# ATSAM4LC2C register map
Vendor: Atmel Corporation; Series: SAM4L; File version: B
CPU: CM4 r0p1, little endian, MPU, no FPU, 4 interrupt priority bits
Registers are 32-bit, write-only, reset 0x0 unless marked. A register's access mark holds for its fields unless they carry their own. Offsets are from the block's base; [hi:lo] are bit positions; 'fields as' and 'values as' point back to an identical list.

## TWIM0 — Two-wire Master Interface 0
Base 0x40018000; register names take the prefix TWIM_
Same registers: TWIM1 0x4001C000, TWIM2 0x40078000, TWIM3 0x4007C000
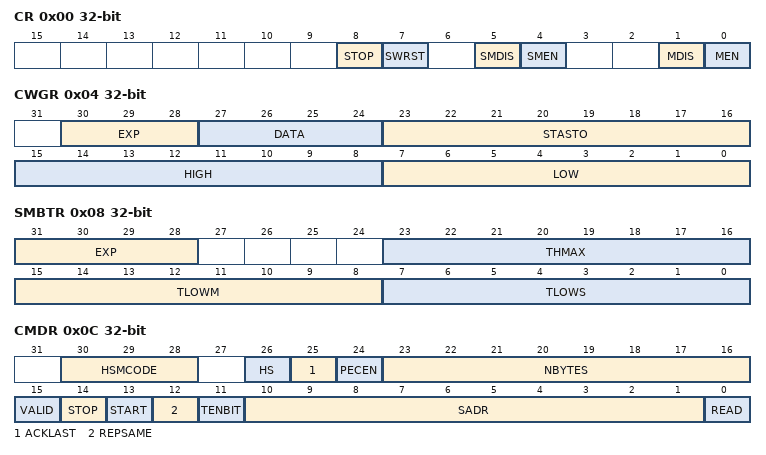
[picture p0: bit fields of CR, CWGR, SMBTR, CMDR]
0x00 CR — Control Register
  [8] STOP — Stop the current transfer
  [7] SWRST — Software Reset
  [5] SMDIS — SMBus Disable
  [4] SMEN — SMBus Enable
  [1] MDIS — Master Disable
  [0] MEN — Master Enable
0x04 CWGR rw — Clock Waveform Generator Register
  [30:28] EXP — Clock Prescaler
  [27:24] DATA — Data Setup and Hold Cycles
  [23:16] STASTO — START and STOP Cycles
  [15:8] HIGH — Clock High Cycles
  [7:0] LOW — Clock Low Cycles
0x08 SMBTR rw — SMBus Timing Register
  [31:28] EXP — SMBus Timeout Clock prescaler
  [23:16] THMAX — Clock High maximum cycles
  [15:8] TLOWM — Master Clock stretch maximum cycles
  [7:0] TLOWS — Slave Clock stretch maximum cycles
0x0C CMDR rw — Command Register
  [30:28] HSMCODE — HS-mode Master Code
  [26] HS — HS-mode
  [25] ACKLAST — ACK Last Master RX Byte
  [24] PECEN — Packet Error Checking Enable
  [23:16] NBYTES — Number of data bytes in transfer
  [15] VALID — CMDR Valid
  [14] STOP — Send STOP condition
  [13] START — Send START condition
  [12] REPSAME — Transfer is to same address as previous address
  [11] TENBIT — Ten Bit Addressing Mode
  [10:1] SADR — Slave Address
  [0] READ — Transfer Direction
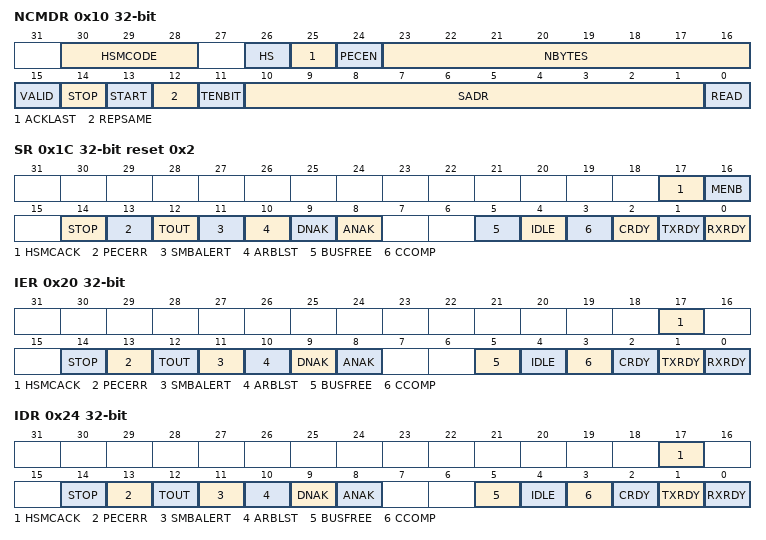
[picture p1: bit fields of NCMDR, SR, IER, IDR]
0x10 NCMDR rw — Next Command Register
  fields as CMDR
0x14 RHR ro — Receive Holding Register
  [7:0] RXDATA — Received Data
0x18 THR — Transmit Holding Register
  [7:0] TXDATA — Data to Transmit
0x1C SR ro reset 0x2 — Status Register
  [17] HSMCACK — ACK in HS-mode Master Code Phase Received
  [16] MENB — Master Interface Enable
  [14] STOP — Stop Request Accepted
  [13] PECERR — PEC Error
  [12] TOUT — Timeout
  [11] SMBALERT — SMBus Alert
  [10] ARBLST — Arbitration Lost
  [9] DNAK — NAK in Data Phase Received
  [8] ANAK — NAK in Address Phase Received
  [5] BUSFREE — Two-wire Bus is Free
  [4] IDLE — Master Interface is Idle
  [3] CCOMP — Command Complete
  [2] CRDY — Ready for More Commands
  [1] TXRDY — THR Data Ready
  [0] RXRDY — RHR Data Ready
0x20 IER — Interrupt Enable Register
  [17] HSMCACK — ACK in HS-mode Master Code Phase Received
  [14] STOP — Stop Request Accepted
  [13] PECERR — PEC Error
  [12] TOUT — Timeout
  [11] SMBALERT — SMBus Alert
  [10] ARBLST — Arbitration Lost
  [9] DNAK — NAK in Data Phase Received
  [8] ANAK — NAK in Address Phase Received
  [5] BUSFREE — Two-wire Bus is Free
  [4] IDLE — Master Interface is Idle
  [3] CCOMP — Command Complete
  [2] CRDY — Ready for More Commands
  [1] TXRDY — THR Data Ready
  [0] RXRDY — RHR Data Ready
0x24 IDR — Interrupt Disable Register
  fields as IER
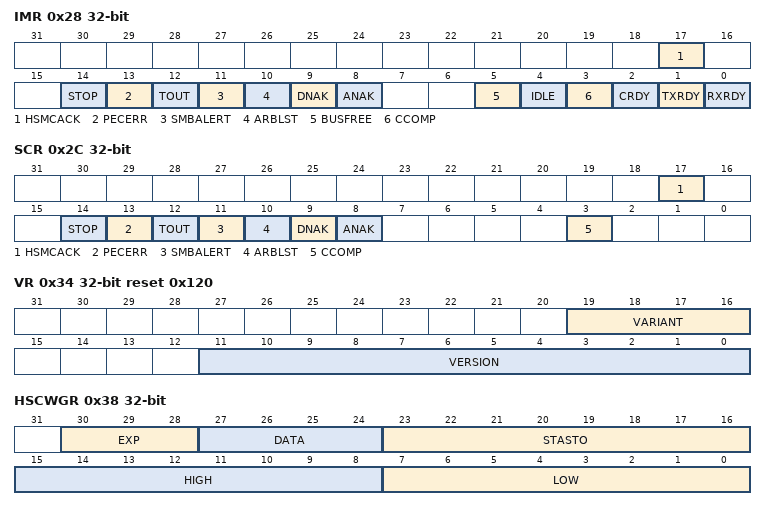
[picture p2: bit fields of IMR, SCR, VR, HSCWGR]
0x28 IMR ro — Interrupt Mask Register
  fields as IER
0x2C SCR — Status Clear Register
  [17] HSMCACK — ACK in HS-mode Master Code Phase Received
  [14] STOP — Stop Request Accepted
  [13] PECERR — PEC Error
  [12] TOUT — Timeout
  [11] SMBALERT — SMBus Alert
  [10] ARBLST — Arbitration Lost
  [9] DNAK — NAK in Data Phase Received
  [8] ANAK — NAK in Address Phase Received
  [3] CCOMP — Command Complete
0x30 PR ro reset 0x1 — Parameter Register
  [0] HS — HS-mode
0x34 VR ro reset 0x120 — Version Register
  [19:16] VARIANT — Variant number
  [11:0] VERSION — Version number
0x38 HSCWGR rw — HS-mode Clock Waveform Generator
  fields as CWGR
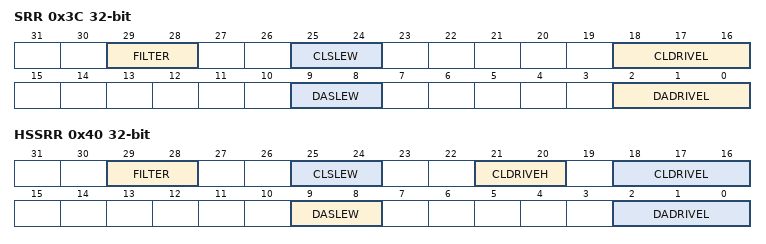
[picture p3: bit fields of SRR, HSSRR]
0x3C SRR rw — Slew Rate Register
  [29:28] FILTER — Input Spike Filter Control
  [25:24] CLSLEW — Clock Slew Limit
  [18:16] CLDRIVEL — Clock Drive Strength LOW
  [9:8] DASLEW — Data Slew Limit
  [2:0] DADRIVEL — Data Drive Strength LOW
0x40 HSSRR rw — HS-mode Slew Rate Register
  [29:28] FILTER — Input Spike Filter Control
  [25:24] CLSLEW — Clock Slew Limit
  [21:20] CLDRIVEH — Clock Drive Strength HIGH
  [18:16] CLDRIVEL — Clock Drive Strength LOW
  [9:8] DASLEW — Data Slew Limit
  [2:0] DADRIVEL — Data Drive Strength LOW
